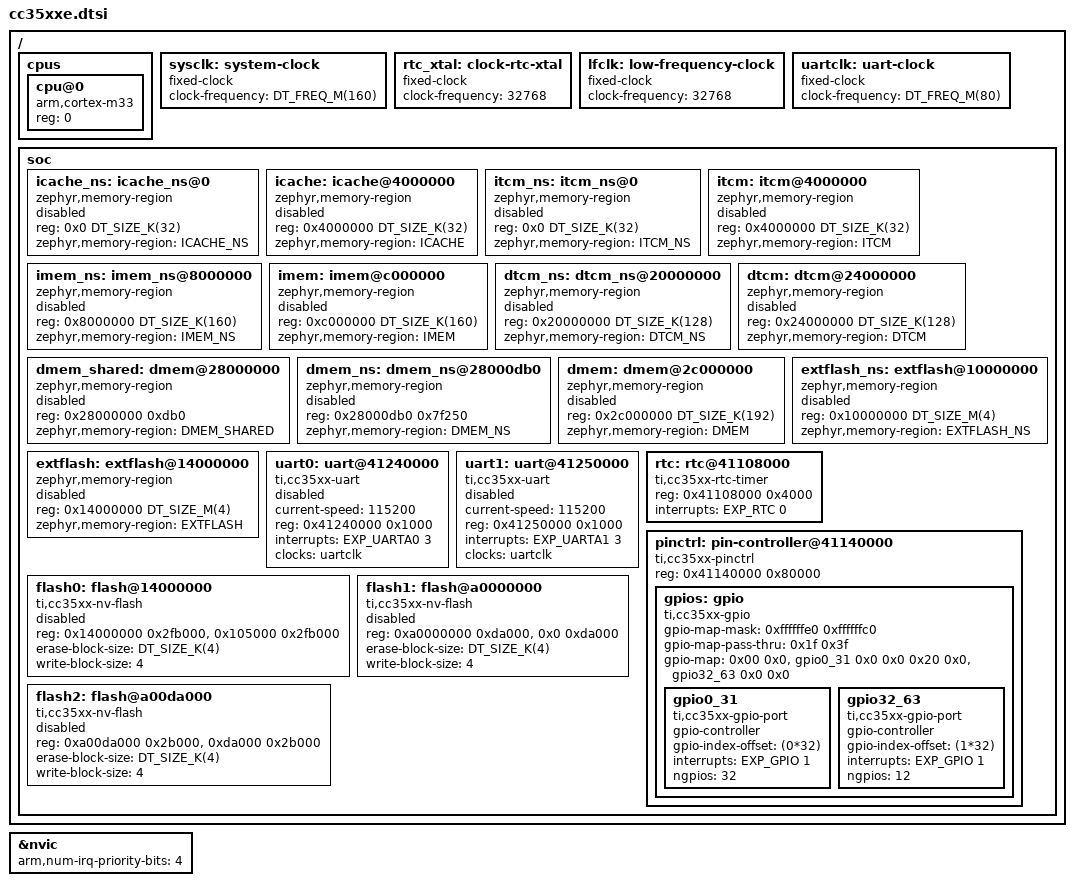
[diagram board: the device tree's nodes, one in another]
/*
 * Copyright (c) 2025 Conclusive Engineering Sp. z o.o.
 *
 * SPDX-License-Identifier: Apache-2.0
 */

#include <mem.h>
#include <freq.h>
#include <arm/armv8-m.dtsi>

#define INT_SP_UART_0_INT_REQ       16
#define INT_SP_UART_1_INT_REQ       17
#define INT_SECURED_GPIO_IRQ_EVT_IND_OUT 33
#define INT_RTC_EVENT_IRQ           65

/*
 * Note: Zephyr uses exception numbers, vs the IRQ used by the TI SimpleLink WFF3 SDK
 * which are offset by 16:
 */
#define EXP_UARTA0   (INT_SP_UART_0_INT_REQ - 16)
#define EXP_UARTA1   (INT_SP_UART_1_INT_REQ - 16)
#define EXP_GPIO     (INT_SECURED_GPIO_IRQ_EVT_IND_OUT - 16)
#define EXP_RTC      (INT_RTC_EVENT_IRQ - 16)

/ {
	cpus {
		#address-cells = <1>;
		#size-cells = <0>;

		cpu@0 {
			device_type = "cpu";
			compatible = "arm,cortex-m33";
			reg = <0>;
		};
	};

	sysclk: system-clock {
		compatible = "fixed-clock";
		clock-frequency = <DT_FREQ_M(160)>;
		#clock-cells = <0>;
	};

	rtc_xtal: clock-rtc-xtal {
		compatible = "fixed-clock";
		clock-frequency = <32768>;
		#clock-cells = <0>;
	};

	lfclk: low-frequency-clock {
		compatible = "fixed-clock";
		clock-frequency = <32768>;
		#clock-cells = <0>;
	};

	uartclk: uart-clock {
		compatible = "fixed-clock";
		clock-frequency = <DT_FREQ_M(80)>;
		#clock-cells = <0>;
	};

	soc {
		/* I-Cache and ITCM size options can be configured independently The user can
		 * decide how to split ITCM and I-Cache in the following configurations:
		 * 1. 32kB I-Cache + 32kB ITCM
		 * 2. 64kB I-Cache + 0kB ITCM
		 */
		icache_ns: icache_ns@0 {
			status = "disabled";
			compatible = "zephyr,memory-region", "mmio-sram";
			reg = <0x0 DT_SIZE_K(32)>;
			zephyr,memory-region = "ICACHE_NS";
		};

		icache: icache@4000000 {
			status = "disabled";
			compatible = "zephyr,memory-region", "mmio-sram";
			reg = <0x4000000 DT_SIZE_K(32)>;
			zephyr,memory-region = "ICACHE";
		};

		itcm_ns: itcm_ns@0 {
			status = "disabled";
			compatible = "zephyr,memory-region", "arm,itcm";
			reg = <0x0 DT_SIZE_K(32)>;
			zephyr,memory-region = "ITCM_NS";
		};

		itcm: itcm@4000000 {
			status = "disabled";
			compatible = "zephyr,memory-region", "arm,itcm";
			reg = <0x4000000 DT_SIZE_K(32)>;
			zephyr,memory-region = "ITCM";
		};

		imem_ns: imem_ns@8000000 {
			status = "disabled";
			compatible = "zephyr,memory-region", "mmio-sram";
			reg = <0x8000000 DT_SIZE_K(160)>;
			zephyr,memory-region = "IMEM_NS";
		};

		imem: imem@c000000 {
			status = "disabled";
			compatible = "zephyr,memory-region", "mmio-sram";
			reg = <0xc000000 DT_SIZE_K(160)>;
			zephyr,memory-region = "IMEM";
		};

		dtcm_ns: dtcm_ns@20000000 {
			status = "disabled";
			compatible = "zephyr,memory-region", "arm,dtcm";
			reg = <0x20000000 DT_SIZE_K(128)>;
			zephyr,memory-region = "DTCM_NS";
		};

		dtcm: dtcm@24000000 {
			status = "disabled";
			compatible = "zephyr,memory-region", "arm,dtcm";
			reg = <0x24000000 DT_SIZE_K(128)>;
			zephyr,memory-region = "DTCM";
		};

		dmem_shared: dmem@28000000 {
			status = "disabled";
			compatible = "zephyr,memory-region", "mmio-sram";
			reg = <0x28000000 0xdb0>;
			zephyr,memory-region = "DMEM_SHARED";
		};

		dmem_ns: dmem_ns@28000db0 {
			status = "disabled";
			compatible = "zephyr,memory-region", "mmio-sram";
			reg = <0x28000db0 0x7f250>;
			zephyr,memory-region = "DMEM_NS";
		};

		dmem: dmem@2c000000 {
			status = "disabled";
			compatible = "zephyr,memory-region", "mmio-sram";
			reg = <0x2c000000 DT_SIZE_K(192)>;
			zephyr,memory-region = "DMEM";
		};

		extflash_ns: extflash@10000000 {
			status = "disabled";
			compatible = "zephyr,memory-region";
			reg = <0x10000000 DT_SIZE_M(4)>;
			zephyr,memory-region = "EXTFLASH_NS";
		};

		extflash: extflash@14000000 {
			status = "disabled";
			compatible = "zephyr,memory-region";
			reg = <0x14000000 DT_SIZE_M(4)>;
			zephyr,memory-region = "EXTFLASH";
		};

		uart0: uart@41240000 {
			compatible = "ti,cc35xx-uart";
			current-speed = <115200>;
			reg = <0x41240000 0x1000>;
			interrupts = <EXP_UARTA0 3>;
			clocks = <&uartclk>;
			status = "disabled";
		};

		uart1: uart@41250000 {
			compatible = "ti,cc35xx-uart";
			current-speed = <115200>;
			reg = <0x41250000 0x1000>;
			interrupts = <EXP_UARTA1 3>;
			clocks = <&uartclk>;
			status = "disabled";
		};

		rtc: rtc@41108000 {
			compatible = "ti,cc35xx-rtc-timer";
			reg = <0x41108000 0x4000>;
			interrupts = <EXP_RTC 0>;
			status = "okay";
		};

		pinctrl: pin-controller@41140000 {
			compatible = "ti,cc35xx-pinctrl";
			reg = <0x41140000 0x80000>;

			gpios: gpio {
				compatible = "ti,cc35xx-gpio";
				status = "okay";
				#gpio-cells = <2>;
				gpio-map-mask = <0xffffffe0 0xffffffc0>;
				gpio-map-pass-thru = <0x1f 0x3f>;
				gpio-map = <
					0x00 0x0 &gpio0_31 0x0 0x0
					0x20 0x0 &gpio32_63 0x0 0x0
				>;

				gpio0_31: gpio0_31 {
					compatible = "ti,cc35xx-gpio-port";
					status = "okay";
					gpio-controller;
					#gpio-cells = <2>;
					gpio-index-offset = <(0*32)>;
					interrupts = <EXP_GPIO 1>;
					ngpios = <32>;
				};

				gpio32_63: gpio32_63 {
					compatible = "ti,cc35xx-gpio-port";
					status = "okay";
					gpio-controller;
					#gpio-cells = <2>;
					gpio-index-offset = <(1*32)>;
					interrupts = <EXP_GPIO 1>;
					ngpios = <12>;
				};
			};
		};

		flash0: flash@14000000 {
			compatible = "ti,cc35xx-nv-flash";
			reg = <0x14000000 0x2fb000>, <0x105000 0x2fb000>;
			erase-block-size = <DT_SIZE_K(4)>;
			write-block-size = <4>;
			status = "disabled";
		};

		flash1: flash@a0000000 {
			compatible = "ti,cc35xx-nv-flash";
			reg = <0xa0000000 0xda000>, <0x0 0xda000>;
			erase-block-size = <DT_SIZE_K(4)>;
			write-block-size = <4>;
			status = "disabled";
		};

		flash2: flash@a00da000 {
			compatible = "ti,cc35xx-nv-flash";
			reg = <0xa00da000 0x2b000>, <0xda000 0x2b000>;
			erase-block-size = <DT_SIZE_K(4)>;
			write-block-size = <4>;
			status = "disabled";
		};

	};
};

&nvic {
	arm,num-irq-priority-bits = <4>;
};
